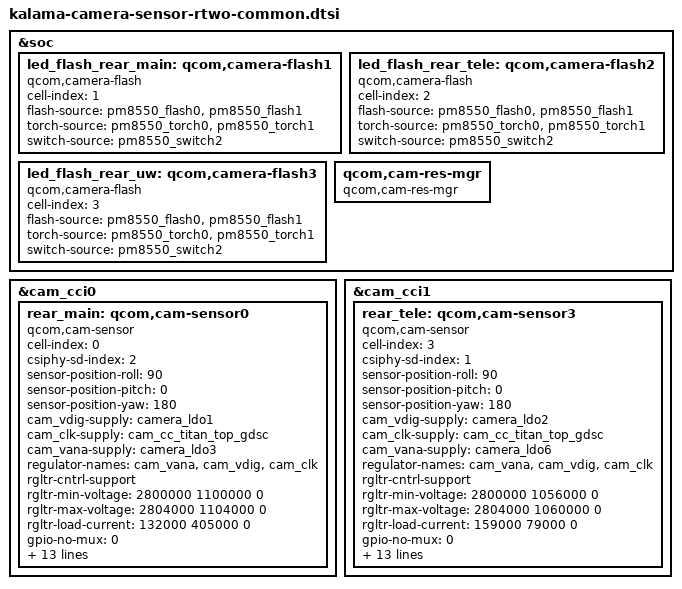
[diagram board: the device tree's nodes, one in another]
/*
   This base is derivated from kalama-camera-sensor-mtp.dtsi
*/
#include <dt-bindings/msm-camera.h>

&soc {
	led_flash_rear_main: qcom,camera-flash1 {
		cell-index = <1>;
		compatible = "qcom,camera-flash";
		flash-source = <&pm8550_flash0 &pm8550_flash1>;
		torch-source = <&pm8550_torch0 &pm8550_torch1>;
		switch-source = <&pm8550_switch2>;
		status = "ok";
	};

	led_flash_rear_tele: qcom,camera-flash2 {
		cell-index = <2>;
		compatible = "qcom,camera-flash";
		flash-source = <&pm8550_flash0 &pm8550_flash1>;
		torch-source = <&pm8550_torch0 &pm8550_torch1>;
		switch-source = <&pm8550_switch2>;
		status = "ok";
	};

	led_flash_rear_uw: qcom,camera-flash3 {
		cell-index = <3>;
		compatible = "qcom,camera-flash";
		flash-source = <&pm8550_flash0 &pm8550_flash1>;
		torch-source = <&pm8550_torch0 &pm8550_torch1>;
		switch-source = <&pm8550_switch2>;
		status = "ok";
	};

	qcom,cam-res-mgr {
		compatible = "qcom,cam-res-mgr";
		status = "ok";
	};
};

&cam_cci0 {
	rear_main: qcom,cam-sensor0 {
		cell-index = <0>;
		compatible = "qcom,cam-sensor";
		csiphy-sd-index = <2>;
		//eeprom-src = <&eeprom_rear_main>;
		sensor-position-roll = <90>;
		sensor-position-pitch = <0>;
		sensor-position-yaw = <180>;

		//cam_vio-supply = <&L4B>;
		cam_vdig-supply = <&camera_ldo1>;
		cam_clk-supply = <&cam_cc_titan_top_gdsc>;
		cam_vana-supply = <&camera_ldo3>;
		//cam_vaf-supply = <&L16B>;
		regulator-names = "cam_vana",
			"cam_vdig","cam_clk";
		rgltr-cntrl-support;
		rgltr-min-voltage = <2800000 1100000 0>;
		rgltr-max-voltage = <2804000 1104000 0>;
		rgltr-load-current = <132000 405000 0>;

		gpio-no-mux = <0>;
		pinctrl-names = "cam_default", "cam_suspend";
		pinctrl-0 = <&cam_sensor_mclk1_active
			&cam_sensor_active_rst1>;
		pinctrl-1 = <&cam_sensor_mclk1_suspend
			&cam_sensor_suspend_rst1>;
		gpios = <&tlmm 101 0>,
			<&tlmm 117 0>;
		gpio-reset = <1>;
		gpio-req-tbl-num = <0 1>;
		gpio-req-tbl-flags = <1 0>;
		gpio-req-tbl-label = "CAMIF_MCLK1",
					"CAM_RESET1";
		cci-master = <CCI_MASTER_0>;
		clocks = <&camcc CAM_CC_MCLK1_CLK>;
		clock-names = "cam_clk";
		clock-cntl-level = "nominal";
		clock-rates = <24000000>;
		status = "ok";
	};
};

&cam_cci1 {
	rear_tele:qcom,cam-sensor3 {
		cell-index = <3>;
		compatible = "qcom,cam-sensor";
		csiphy-sd-index = <1>;
		sensor-position-roll = <90>;
		sensor-position-pitch = <0>;
		sensor-position-yaw = <180>;
		//eeprom-src = <&eeprom_rear_tele>;
		//actuator-src = <&actuator_rear_tele>;
		//led-flash-src = <&led_flash_rear_tele>;
		//cam_vio-supply = <&L4B>;
		cam_vdig-supply = <&camera_ldo2>;
		cam_clk-supply = <&cam_cc_titan_top_gdsc>;
		cam_vana-supply = <&camera_ldo6>;
		//cam_vaf-supply = <&camera_ldo7>;
		regulator-names = "cam_vana",
			"cam_vdig", "cam_clk";
		rgltr-cntrl-support;
		rgltr-min-voltage = <2800000 1056000 0>;
		rgltr-max-voltage = <2804000 1060000 0>;
		rgltr-load-current = <159000 79000 0>;
		gpio-no-mux = <0>;
		pinctrl-names = "cam_default", "cam_suspend";
		pinctrl-0 = <&cam_sensor_mclk3_active
				 &cam_sensor_active_rst3>;
		pinctrl-1 = <&cam_sensor_mclk3_suspend
				 &cam_sensor_suspend_rst3>;
		gpios = <&tlmm 103 0>,
			<&tlmm 119 0>;
		gpio-reset = <1>;
		gpio-req-tbl-num = <0 1>;
		gpio-req-tbl-flags = <1 0>;
		gpio-req-tbl-label = "CAMIF_MCLK3",
					"CAM_RESET3";
		cci-master = <CCI_MASTER_0>;
		clocks = <&camcc CAM_CC_MCLK3_CLK>;
		clock-names = "cam_clk";
		clock-cntl-level = "nominal";
		clock-rates = <24000000>;
		status = "ok";
	};
};

